# M2003 register map
File version: 1.0
M2003 SVD file
Registers are 32-bit, read-write, reset 0x0 unless marked. A register's access mark holds for its fields unless they carry their own. Offsets are from the block's base; lines under a group give offsets from that group; [hi:lo] are bit positions; {n}, {i} and the like mark numbered series; 'fields as' and 'values as' point back to an identical list; <NAME> marks a mode.

## Memory map
0x40000000 SYS blocks up to offset 0x1F0 — SYS Register Map
0x40000200 CLK blocks up to offset 0xB4 — CLK Register Map
0x40000300 NMI size 0x8 — NMI Register Map
0x40004000 GPIO blocks up to offset 0x980 — GPIO Register Map
0x4000C000 FMC blocks up to offset 0x50 — FMC Register Map
0x40040000 WDT size 0xC — WDT Register Map
0x40040100 WWDT size 0x10 — WWDT Register Map
0x40043000 ADC0 blocks up to offset 0xA4 — ADC0 Register Map
0x40050000 TMR0 blocks up to offset 0x84 — TIMER Register Map
0x40050100 TMR1 blocks up to offset 0x28 — TIMER Register Map
0x40051000 TMR2 blocks up to offset 0x84 — TIMER Register Map
0x40051100 TMR3 blocks up to offset 0x28 — TIMER Register Map
0x40058000 PWM blocks up to offset 0x334 — PWM Register Map
0x40070000 UART0 blocks up to offset 0x4C — UART Register Map
0x40071000 UART1 blocks up to offset 0x4C — UART Register Map
0x40080000 I2C0 blocks up to offset 0x50 — I2C Register Map
0x400B4000 ECAP0 size 0x2C — ECAP Register Map
0x400D0000 UUART0 blocks up to offset 0x68 — USCIUART Register Map
0x400D0000 USPI0 blocks up to offset 0x68 — USCISPI Register Map
0x400D0000 UI2C0 blocks up to offset 0x90 — USCII2C Register Map
0xE000E000 SCS blocks up to offset 0xD28 — SYST_SCR Register Map
0xE000E100 NVIC blocks up to offset 0x340 — NVIC Register Map

## NVIC — NVIC Register Map
Base 0xE000E100
0x00 NVIC_ISER0 — IRQ00 ~ IRQ31 Set-enable Control Register
  [31:0] SETENA — Interrupt Set Enable Bit. The NVIC_ISER0-NVIC_ISER1 registers enable interrupts, and show which interrupts are enabled. Write Operation:
    0=No effect. Interrupt Disabled; 1=Interrupt Enabled
0x04 NVIC_ISER1 — IRQ32 ~ IRQ63 Set-enable Control Register
  fields as NVIC_ISER0
0x08 NVIC_ISER2 — IRQ64 ~ IRQ95 Set-enable Control Register
0x80 NVIC_ICER0 — IRQ00 ~ IRQ31 Clear-enable Control Register
  [31:0] CALENA — Interrupt Clear Enable Bit. The NVIC_ICER0-NVIC_ICER1 registers disable interrupts, and show which interrupts are enabled. Write Operation:
    0=No effect. Interrupt Disabled; 1=Interrupt Disabled. Interrupt Enabled
0x84 NVIC_ICER1 — IRQ32 ~ IRQ63 Clear-enable Control Register
  fields as NVIC_ICER0
0x88 NVIC_ICER2 — IRQ64 ~ IRQ95 Clear-enable Control Register
0x100 NVIC_ISPR0 — IRQ00 ~ IRQ31 Set-pending Control Register
  [31:0] SETPEND — Interrupt Set-pending. The NVIC_ISPR0-NVIC_ISPR1 registers force interrupts into the pending state, and show which interrupts are pending. Write Operation:
    0=No effect. Interrupt is not pending; 1=Changes interrupt state to pending. Interrupt is pending
0x104 NVIC_ISPR1 — IRQ32 ~ IRQ63 Set-pending Control Register
  fields as NVIC_ISPR0
0x108 NVIC_ISPR2 — IRQ64 ~ IRQ95 Set-pending Control Register
0x180 NVIC_ICPR0 — IRQ00 ~ IRQ31 Clear-pending Control Register
  [31:0] CALPEND — Interrupt Clear-pending. The NVIC_ICPR0-NVIC_ICPR1 registers remove the pending state from interrupts, and show which interrupts are pending. Write Operation:
    0=No effect. Interrupt is not pending; 1=Removes pending state an interrupt. Interrupt is pending
0x184 NVIC_ICPR1 — IRQ32 ~ IRQ63 Clear-pending Control Register
  fields as NVIC_ICPR0
0x188 NVIC_ICPR2 — IRQ64 ~ IRQ95 Clear-pending Control Register
0x200 NVIC_IABR0 — IRQ00 ~ IRQ31 Active Bit Register
  [31:0] ACTIVE — Interrupt Active Flags. The NVIC_IABR0-NVIC_IABR1 registers indicate which interrupts are active.
    0=Interrupt not active; 1=Interrupt active
0x204 NVIC_IABR1 — IRQ32 ~ IRQ63 Active Bit Register
  [31:0] ACTIVE — Interrupt Active Flags. The NVIC_IABR0-NVIC_IABR1 registers indicate which interrupts are active.
    0=interrupt not active; 1=interrupt active
0x208 NVIC_IABR2 — IRQ64 ~ IRQ95 Active Bit Register
0x280 NVIC_ITNS0 — IRQ00 ~ IRQ31 Interrupt Target Non-secure Register
  [31:0] ITNS — Interrupt Target Non-secure Register. The NVIC_ITNS0-NVIC_INTS1 registers, determines whether each interrupt targets Non-secure or Secure state. This register is RAZ/WI when accessed as Non-secure.
    0=Interrupt targets Secure state; 1=Interrupt targets Non-secure state
0x284 NVIC_ITNS1 — IRQ32 ~ IRQ63 Interrupt Target Non-secure Register
  [31:0] ITNS — Interrupt Target Non-secure Register. The NVIC_ITNS0-NVIC_INTS1 registers, determines whether each interrupt targets Non-secure or Secure state. Note: This register is RAZ/WI when accessed as Non-secure.
    values as NVIC_ITNS0.ITNS
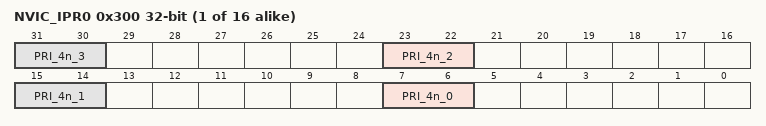
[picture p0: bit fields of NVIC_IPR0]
{0x300+4i} NVIC_IPR{i} (i=0..15) — IRQ0 ~ IRQ63 Priority Control Register
  [8n+7:8n+6] PRI_4n_{n} (n=0..3) — Priority of IRQ_4n+{n} '0' denotes the highest priority and '3' denotes the lowest priority.
